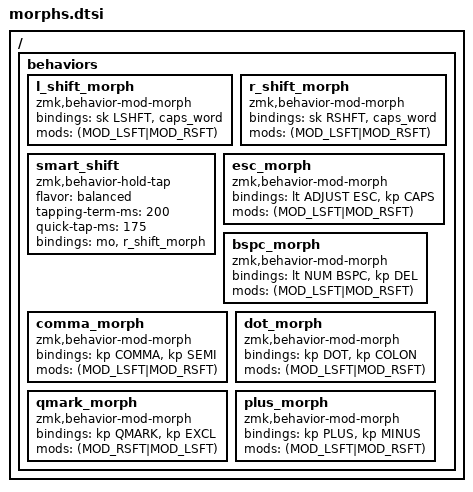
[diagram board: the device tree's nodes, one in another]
/ {
  behaviors {

    /*
      * Sticky shift + Caps Word
      *
      * Usage: &l_shift_morph or &r_shift_morph
      * Tap: Sticky shift
      * HMR-Shift-Tap: Caps Word
      * Double Tap: Caps Word
      *   - The first tap activates sticky shift mod
      *   - The second tap is now a shift + press, which activates
      *     the mod morph
      * Hold: Shift
      *
      * Credits to urob for this genius combo.
      */
    l_shift_morph: l_shift_morph {
      compatible = "zmk,behavior-mod-morph";
      /* #binding-cells = <0>; */

      bindings = <&sk LSHFT>, <&caps_word>;

      mods = <(MOD_LSFT|MOD_RSFT)>;
    };

    r_shift_morph: r_shift_morph {
      compatible = "zmk,behavior-mod-morph";
      /* #binding-cells = <0>; */

      bindings = <&sk RSHFT>, <&caps_word>;

      mods = <(MOD_LSFT|MOD_RSFT)>;
    };

    /*
    * Sticky shift + Caps Word | hold: swith to fn layer
    */
    smart_shift: smart_shift  {
      compatible = "zmk,behavior-hold-tap";

      flavor = "balanced";
      tapping-term-ms = <200>;
      quick-tap-ms = <175>;
      bindings = <&mo>, <&r_shift_morph>;
    };
    /*
      * Esc + Caps
      *
      * Usage: &esc_morph
      * Tap: Esc
      * HMR-Shift-Tap: Caps
      * Hold: switch to adjust layer
      *
      * Credits to urob for this genius combo.
      */
    esc_morph: esc_morph {
      compatible = "zmk,behavior-mod-morph";
      #binding-cells = <0>;

      bindings = <&lt ADJUST ESC>, <&kp CAPS>;

      mods = <(MOD_LSFT|MOD_RSFT)>;
    };

    /*
      * Shifted Backspace deletes
      *
      * Usage: &bspc_morph
      * Tap: Backspace
      * Shift-Tap: Delete
      * Hold: switch num layer
      */
    bspc_morph: bspc_morph {
      compatible = "zmk,behavior-mod-morph";
      bindings = <&lt NUM BSPC>, <&kp DEL>;
      #binding-cells = <0>;
      mods = <(MOD_LSFT|MOD_RSFT)>;
    };


    /*
      * Shifted comma types semicoln
      *
      * Usage: &comma_morph
      * Tap: ,
      * Shift-Tap: ;
      */
    comma_morph: comma_morph {
      compatible = "zmk,behavior-mod-morph";
      #binding-cells = <0>;
      bindings = <&kp COMMA>, <&kp SEMI>;
      mods = <(MOD_LSFT|MOD_RSFT)>;
    };
    /*
      * Shifted dot types colon
      *
      * Usage: &dot_morph
      * Tap: .
      * Shift-Tap: :
      */
    dot_morph: dot_morph {
      compatible = "zmk,behavior-mod-morph";
      #binding-cells = <0>;
      bindings = <&kp DOT>, <&kp COLON>;
      mods = <(MOD_LSFT|MOD_RSFT)>;
    };
    /*
      * Shifted qmark types excl
      *
      * Usage: &qmark_morph
      * Tap: ?
      * Shift-Tap: !
      */
    qmark_morph: qmark_morph {
      compatible = "zmk,behavior-mod-morph";
      #binding-cells = <0>;
      bindings = <&kp QMARK>, <&kp EXCL>;
      mods = <(MOD_RSFT|MOD_LSFT)>;
    };
    /*
      * Shifted plus types minus (-)
      *
      * Usage: &plus_morph
      * Tap: `
      * Shift-Tap: ^
      */
    plus_morph: plus_morph {
      compatible = "zmk,behavior-mod-morph";
      #binding-cells = <0>;
      bindings = <&kp PLUS>, <&kp MINUS>;
      mods = <(MOD_LSFT|MOD_RSFT)>;
    };
  };
};
